# USB_USB2SS_USB2SS_CFG_0F900000h register map
Vendor: Texas Instruments
Peripheral module from a debugger description file (folder AM275x).
Registers are 32-bit, access per field, reset 0x0 unless marked. A register's access mark holds for its fields unless they carry their own. Offsets are as the file gives them; lines under a group give offsets from that group; [hi:lo] are bit positions; {n}, {i} and the like mark numbered series; 'fields as' and 'values as' point back to an identical list; <NAME> marks a mode.

## USB2SS_USB2SS_CFG
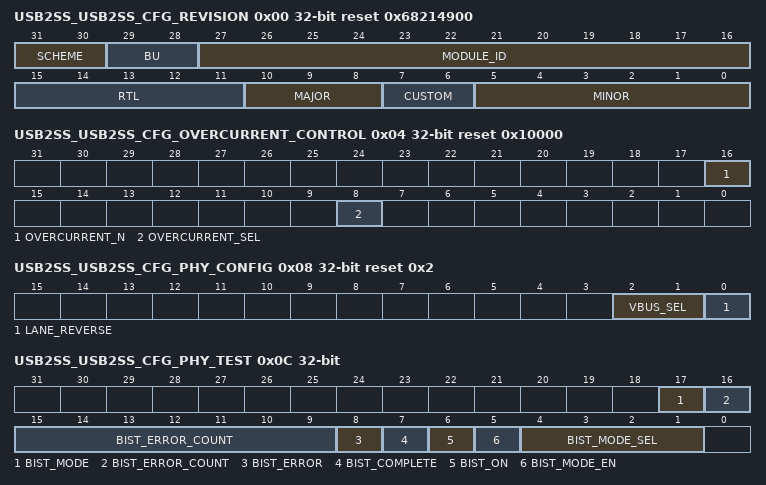
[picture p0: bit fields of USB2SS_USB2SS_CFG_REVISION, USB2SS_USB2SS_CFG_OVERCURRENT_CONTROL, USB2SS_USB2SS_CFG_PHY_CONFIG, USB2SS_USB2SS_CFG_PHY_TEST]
0x00 USB2SS_USB2SS_CFG_REVISION ro reset 0x68214900 — The Revision Register contains the major and minor revisions for the module.
  [31:30] SCHEME — PID register scheme Reset Source: cfg_srst_n
  [29:28] BU — Business Unit: 10 = Processors Reset Source: cfg_srst_n
  [27:16] MODULE_ID — Module ID Reset Source: cfg_srst_n
  [15:11] RTL — RTL revision. Will vary depending on release. Reset Source: cfg_srst_n
  [10:8] MAJOR — Major revision Reset Source: cfg_srst_n
  [7:6] CUSTOM — Custom Reset Source: cfg_srst_n
  [5:0] MINOR — Minor revision Reset Source: cfg_srst_n
0x04 USB2SS_USB2SS_CFG_OVERCURRENT_CONTROL reset 0x10000 — This register contains bits for indicating overcurrent condition on VBUS to Controller
  [16] OVERCURRENT_N rw — Overcurrent indicator to the Controller Reset Source: cfg_srst_n
  [8] OVERCURRENT_SEL rw — Overcurrent MMR select. Has to be written before setting pwrup_rst_n bit. 1 - overcurrent MMR bit is used, 0 - port_overcurrent_n input is used Reset Source: cfg_srst_n
0x08 USB2SS_USB2SS_CFG_PHY_CONFIG reset 0x2 — Wrapper register containing static settings. All bits in this register directly drive the USB2 PHY inputs. Please refer to USB2 PHY user guide for more information.
  [2:1] VBUS_SEL rw — This register directly drives the vbus_sel[1:0] input to the PHY. VBUS select - 00: VBUS = 5.25V/3.3V, 01: VBUS/3 external divider is active, so VBUS could be upto 11V. Reset Source: cfg_srst_n
  [0] LANE_REVERSE rw — This register directly drives the lane_reverse input to USB2 PHY. Lane reverse selection. When set, this bit indicates that D+ and D- lines have to be swapped. Reset Source: cfg_srst_n
0x0C USB2SS_USB2SS_CFG_PHY_TEST — Register containing PLL bypass select, BIST control and status
  [17] BIST_MODE rw — Set for bist mode. This is used for overriding PHY ports for BIST. Reset Source: cfg_srst_n
  [16:9] BIST_ERROR_COUNT ro — Number of bytes that have errors while running BIST. The count resets when bist_on is set. Reset Source: cfg_srst_n
  [8] BIST_ERROR ro — If set, this bit indicates that BIST completed with error. Reset Source: cfg_srst_n
  [7] BIST_COMPLETE ro — If set, this bit indicates that the BIST operation is completed. Reset Source: cfg_srst_n
  [6] BIST_ON rw — Setting this bit starts the BIST operation. Reset Source: cfg_srst_n
  [5] BIST_MODE_EN rw — BIST Mode Enable. 0 = BIST not enabled, 1 = BIST enabled Reset Source: cfg_srst_n
  [4:1] BIST_MODE_SEL rw — BIST Mode Selection. bist_mode_sel[3]: 0 = 8-bit interface, 1 = 16-bit interface; bist_mode_sel[2]: 0 = error injection disabled, 1 = error injection enabled; bist_mode_sel[1]: 0 = device mode, 1 = host mode; bist_mode_sel[0]: 0 = High Speed mode, 1 = Full Speed mode. Reset Source: cfg_srst_n
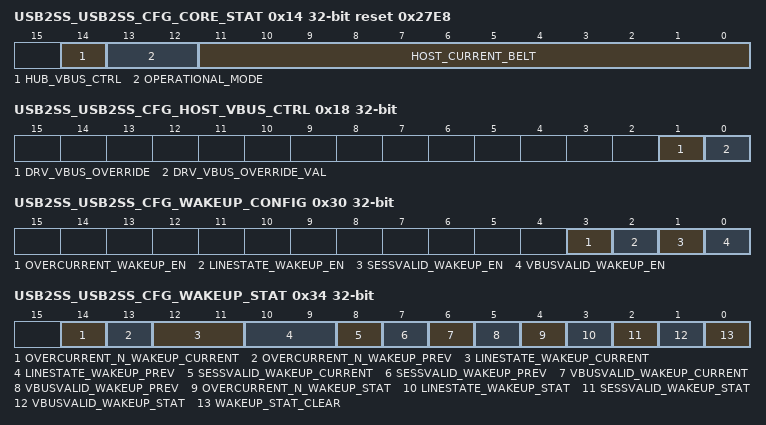
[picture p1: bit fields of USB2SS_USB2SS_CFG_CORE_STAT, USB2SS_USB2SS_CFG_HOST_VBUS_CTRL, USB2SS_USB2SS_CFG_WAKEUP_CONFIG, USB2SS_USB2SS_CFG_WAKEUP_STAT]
0x14 USB2SS_USB2SS_CFG_CORE_STAT ro reset 0x27E8 — Register containing miscellaneous status bits from the core
  [14] HUB_VBUS_CTRL — Indicates whether core is asking for VBUS to be turned on in host mode. Reset Source: cfg_srst_n
  [13:12] OPERATIONAL_MODE — Indicates current operational mode of Controller. This directly reflects the value programmed into GCTL.PRTCAPDIR Controller register. 2'b01 - Host, 2'b10 - Device. Reset Source: cfg_srst_n
  [11:0] HOST_CURRENT_BELT — Indicates minimum of all received device BELT values and the BELT value set by the Set Latency Tolerance Value command. Reset Source: cfg_srst_n
0x18 USB2SS_USB2SS_CFG_HOST_VBUS_CTRL rw — Register containing software bit for overriding drive VBUS
  [1] DRV_VBUS_OVERRIDE — Setting this bit enables drive VBUS override. Drive VBUS output reflects drv_vbus_override_val field value. Reset Source: cfg_srst_n
  [0] DRV_VBUS_OVERRIDE_VAL — Drive VBUS output override value. Reset Source: cfg_srst_n
0x1C USB2SS_USB2SS_CFG_MODE_CONTROL rw — Register containing software bit for indicating DRD mode is determined
  [0] MODE_VALID — For DRD applications, software sets this bit when the role is determined based on connect event and ID value from GPIO. Software clears this bit when a disconnect event happens and role is no longer valid. Software can also set this once during initialization for fixed role applications. Reset Source: cfg_srst_n
0x30 USB2SS_USB2SS_CFG_WAKEUP_CONFIG — Register containing low power mode wakeup enables
  [3] OVERCURRENT_WAKEUP_EN rw — overcurrent event wakeup enable Reset Source: cfg_srst_n
  [2] LINESTATE_WAKEUP_EN rw — linestate event wakeup enable Reset Source: cfg_srst_n
  [1] SESSVALID_WAKEUP_EN rw — SESSVALID event wakeup enable Reset Source: cfg_srst_n
  [0] VBUSVALID_WAKEUP_EN rw — VBUSVALID event wakeup enable Reset Source: cfg_srst_n
0x34 USB2SS_USB2SS_CFG_WAKEUP_STAT access not given — Register containing low power mode status bits. The status bits are set when the corresponding wakeup event happens and the corresponding enable in WAKEUP_CONFIG MMR is set. In addition, these bits are only set if clockstop request from PSC is active in order to ensure that these are captured only during low power mode and not during regular operation. These bits can only be set by hardware and once set, they can only be cleared by software by setting wakeup_stat_clear field.
  [14] OVERCURRENT_N_WAKEUP_CURRENT ro — overcurrent_n current value during wakeup event Reset Source: cfg_srst_n
  [13] OVERCURRENT_N_WAKEUP_PREV ro — overcurrent_n previous value during wakeup event Reset Source: cfg_srst_n
  [12:11] LINESTATE_WAKEUP_CURRENT ro — Linestate current value during wakeup event Reset Source: cfg_srst_n
  [10:9] LINESTATE_WAKEUP_PREV ro — Linestate previous value during wakeup event Reset Source: cfg_srst_n
  [8] SESSVALID_WAKEUP_CURRENT ro — SESSVALID current value during wakeup event Reset Source: cfg_srst_n
  [7] SESSVALID_WAKEUP_PREV ro — SESSVALID previous value during wakeup event Reset Source: cfg_srst_n
  [6] VBUSVALID_WAKEUP_CURRENT ro — VBUSVALID current value during wakeup event Reset Source: cfg_srst_n
  [5] VBUSVALID_WAKEUP_PREV ro — VBUSVALID previous value during wakeup event Reset Source: cfg_srst_n
  [4] OVERCURRENT_N_WAKEUP_STAT ro — overcurrent_n event wakeup status. This is only looking for change on port_overcurrent_n input and does not include overcurrent MMR. This is because wakeup is required only for a port event and for any software write to happen, SOC should already have been awake. Also SOC may be tying off port_overcurrent_n, so this event may never trigger. Reset Source: cfg_srst_n
  [3] LINESTATE_WAKEUP_STAT ro — linestate event wakeup status Reset Source: cfg_srst_n
  [2] SESSVALID_WAKEUP_STAT ro — SESSVALID event wakeup status Reset Source: cfg_srst_n
  [1] VBUSVALID_WAKEUP_STAT ro — VBUSVALID event wakeup status Reset Source: cfg_srst_n
  [0] WAKEUP_STAT_CLEAR — Clears all the *_wakeup_stat bits in this register Reset Source: cfg_srst_n (access R/W1TC)
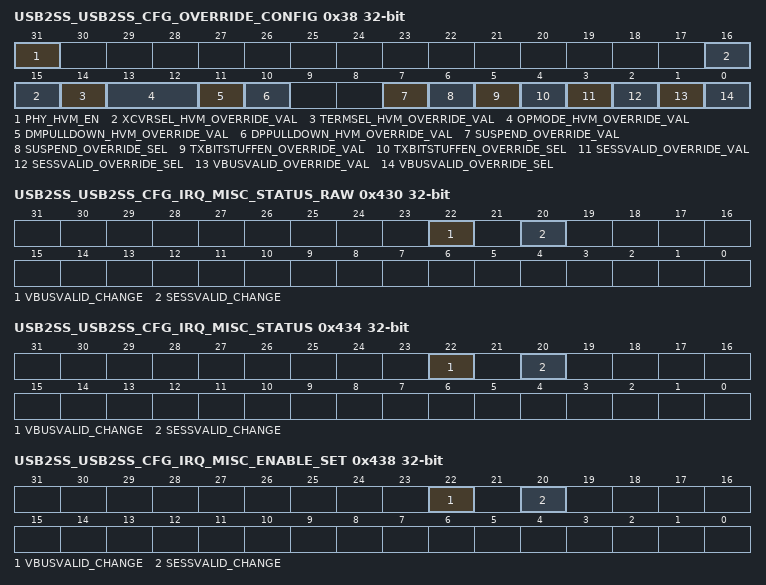
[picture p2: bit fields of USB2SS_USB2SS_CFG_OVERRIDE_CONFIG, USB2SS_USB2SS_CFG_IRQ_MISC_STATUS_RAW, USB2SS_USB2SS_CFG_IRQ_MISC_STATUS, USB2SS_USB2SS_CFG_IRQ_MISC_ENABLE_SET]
0x38 USB2SS_USB2SS_CFG_OVERRIDE_CONFIG rw — Register containing various overrides
  [31] PHY_HVM_EN — Enable PHY HVM overrides. Reset Source: cfg_srst_n
  [16:15] XCVRSEL_HVM_OVERRIDE_VAL — Override value for PHY xcvr input. The value in this field is applied to PHY xcvrsel input if phy_hvm_en bit in this register is set. Reset Source: cfg_srst_n
  [14] TERMSEL_HVM_OVERRIDE_VAL — Override value for PHY termsel input. The value in this field is applied to PHY termsel input if phy_hvm_en bit in this register is set. Reset Source: cfg_srst_n
  [13:12] OPMODE_HVM_OVERRIDE_VAL — Override value for PHY opmode input. The value in this field is applied to PHY opmode input if phy_hvm_en bit in this register is set. Reset Source: cfg_srst_n
  [11] DMPULLDOWN_HVM_OVERRIDE_VAL — Override value for PHY dmpulldown input. The value in this field is applied to PHY dmpulldown input if phy_hvm_en bit in this register is set. Reset Source: cfg_srst_n
  [10] DPPULLDOWN_HVM_OVERRIDE_VAL — Override value for PHY dppulldown input. The value in this field is applied to PHY dppulldown input if phy_hvm_en bit in this register is set. Reset Source: cfg_srst_n
  [7] SUSPEND_OVERRIDE_VAL — Suspend override value. 0 - suspendm is asserted and clockstop idle term indicates idle, 1 - suspendm is deasserted and clockstop idle term indicates non-idle. Reset Source: cfg_srst_n
  [6] SUSPEND_OVERRIDE_SEL — Suspend override selector. This has to be set to override utmi_suspend_n from Controller that goes to clockstop idle. This does not affect suspend going to PHY. Only purpose of this is to ease clockstop interface DV. Reset Source: cfg_srst_n
  [5] TXBITSTUFFEN_OVERRIDE_VAL — TXBITSTUFFENABLE override value Reset Source: cfg_srst_n
  [4] TXBITSTUFFEN_OVERRIDE_SEL — TXBITSTUFFENABLE override selector. This has to be set to override TXBITSTUFFENABLE to PHY. Reset Source: cfg_srst_n
  [3] SESSVALID_OVERRIDE_VAL — SESSVALID override value. 1 - Session is valid, 0 - Session is not valid Reset Source: cfg_srst_n
  [2] SESSVALID_OVERRIDE_SEL — SESSVALID override selector. This has to be set to override sessvalid from PHY to Controller. Reset Source: cfg_srst_n
  [1] VBUSVALID_OVERRIDE_VAL — VBUSVALID override value. 1 - VBUS is valid, 0 - VBUS is not valid Reset Source: cfg_srst_n
  [0] VBUSVALID_OVERRIDE_SEL — VBUSVALID override selector. This has to be set to override vbusvalid from PHY to Controller. Reset Source: cfg_srst_n
0x430 USB2SS_USB2SS_CFG_IRQ_MISC_STATUS_RAW access not given — The IRQ_STATUS_RAW_MISC register allows the usbss interrupt sources to be manually set when writing a 1 to a specific bit. Write 0: No action Write 1: Set event Read 0: No event pending Read 1: Event pending
  [22] VBUSVALID_CHANGE — Set when VBUSVALID changes state Reset Source: cfg_srst_n (access R/W1TS)
  [20] SESSVALID_CHANGE — Set when SESSVALID changes state Reset Source: cfg_srst_n (access R/W1TS)
0x434 USB2SS_USB2SS_CFG_IRQ_MISC_STATUS access not given — The IRQ_STATUS_MISC register allows the usbss interrupt sources to be manually cleared when writing a 1 to a specific bit. Write 0: No action Write 1: Clear event Read 0: No event pending Read 1: Event pending
  [22] VBUSVALID_CHANGE — Set when VBUSVALID changes state Reset Source: cfg_srst_n (access R/W1TC)
  [20] SESSVALID_CHANGE — Set when SESSVALID changes state Reset Source: cfg_srst_n (access R/W1TC)
0x438 USB2SS_USB2SS_CFG_IRQ_MISC_ENABLE_SET access not given — The IRQ_ENABLE_SET_MISC register allows the usbss interrupt sources to be manually enabled when writing a 1 to a specific bit. Write 0: No action Write 1: Enable event Read 0: Event is disabled Read 1: Event is enabled
  [22] VBUSVALID_CHANGE — Event enable Reset Source: cfg_srst_n (access R/W1TS)
  [20] SESSVALID_CHANGE — Event enable Reset Source: cfg_srst_n (access R/W1TS)
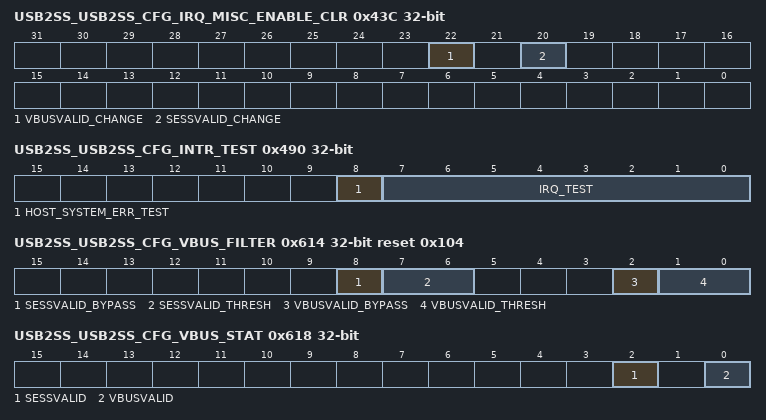
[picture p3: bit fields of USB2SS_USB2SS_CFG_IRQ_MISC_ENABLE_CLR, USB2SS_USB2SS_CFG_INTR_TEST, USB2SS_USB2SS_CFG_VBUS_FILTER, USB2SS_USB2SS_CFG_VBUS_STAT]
0x43C USB2SS_USB2SS_CFG_IRQ_MISC_ENABLE_CLR access not given — The IRQ_ENABLE_CLR_MISC register allows the usbss interrupt sources to be manually disabled when writing a 1 to a specific bit. Write 0: No action Write 1: Disable event Read 0: Event is disabled Read 1: Event is enabled
  [22] VBUSVALID_CHANGE — Event enable Reset Source: cfg_srst_n (access R/W1TC)
  [20] SESSVALID_CHANGE — Event enable Reset Source: cfg_srst_n (access R/W1TC)
0x440 USB2SS_USB2SS_CFG_IRQ_MISC_EOI rw — EOI vector for re-triggering interrupts
  [0] EOI_VECTOR — EOI vector for misc interrupt. Has to be written to 0 after ISR services misc interrupt. Reset Source: cfg_srst_n
0x490 USB2SS_USB2SS_CFG_INTR_TEST rw — Register for overriding various Controller interrupts for easy activation during DV. NOTE: This is only for internal purposes and should NOT be used during functional operation.
  [8] HOST_SYSTEM_ERR_TEST — Test for host system error interrupt. Set 1 to cause host_system_error_intr to trigger and clear this bit to clear the interrupt condition. Reset Source: cfg_srst_n
  [7:0] IRQ_TEST — Test for irq interrupts from core. Each bit sets corresponding irq_intr bit. Set 1 to each bit based on whether that interrupt needs to trigger and clear the bit in ISR to clear interrupt condition. Reset Source: cfg_srst_n
0x614 USB2SS_USB2SS_CFG_VBUS_FILTER reset 0x104 — The vbus comparator signals may be filtered by controlling these register values.
  [8] SESSVALID_BYPASS rw — 0= use filter, 1= bypass filter Reset Source: cfg_srst_n
  [7:6] SESSVALID_THRESH rw — 00= 1us,01= 100us,10= 5ms,11= 50ms. 4 utmi_clk latency for sessvalid Reset Source: cfg_srst_n
  [2] VBUSVALID_BYPASS rw — 0= use filter, 1= bypass filter for vbusvalid Reset Source: cfg_srst_n
  [1:0] VBUSVALID_THRESH rw — 00= 1us,01= 100us,10= 5ms,11= 50ms. 4 utmi_clk latency for vbusvalid Reset Source: cfg_srst_n
0x618 USB2SS_USB2SS_CFG_VBUS_STAT ro — Status bits of VBUS detected signals after filter.
  [2] SESSVALID — Filtered SESSVALID Reset Source: cfg_srst_n
  [0] VBUSVALID — Filtered VBUSVALID Reset Source: cfg_srst_n
0x708 USB2SS_USB2SS_CFG_DEBUG_CFG rw — Configuration of debug data for observation. 0x0 or 0x7 = debug outputs are tied low, 0x1 = debug outputs are UTMI interface signals, 0x2 = debug outputs are Controller debug[31:0] output 0x3 = debug outputs are Controller debug[63:32] output, 0x4 = debug outputs are clk_gate_ctrl and debug[66:64] Controller outputs, 0x5 = debug outputs are controller logic_analyzer_trace[31:0], 0x6 = debug outputs are controller logic_analyzer_trace[63:32]
  [2:0] SEL — selection of observed local signals Reset Source: cfg_srst_n
0x70C USB2SS_USB2SS_CFG_DEBUG_DATA ro — Debug data
  [31:0] VAL — tmp Reset Source: cfg_srst_n
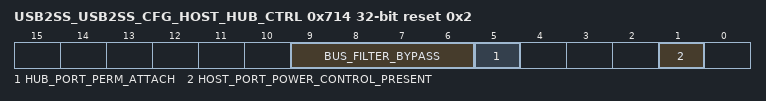
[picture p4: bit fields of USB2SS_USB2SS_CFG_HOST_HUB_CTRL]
0x714 USB2SS_USB2SS_CFG_HOST_HUB_CTRL reset 0x2 — The HOST_HUB_CTRL Register is a collection of various input signals that control the xHC controllers Host or Hub interfaces. These signals are used regardless if a Host or Hub is implemented or not.
  [9:6] BUS_FILTER_BYPASS rw — Bus Filter Bypass bit [0]: bypass the filter for vbusvalid bit bit [2]: bypass the filter for sessvalid Reset Source: cfg_srst_n
  [5] HUB_PORT_PERM_ATTACH rw — Indicates if the device attached to a downstream port is permanently attached or not. Bit 6 is the USB2 port and bit 7 is the SS port. 0 - Not permanently attached 1 - Permanently attached Reset Source: cfg_srst_n
  [1] HOST_PORT_POWER_CONTROL_PRESENT rw — This port defines the bit [3] of Capability Parameters (HCCPARAMS). Change the PPC value through the pin Port Power Control (PPC). This indicates whether the host controller implementation includes port power control. 0 - Indicates that the port does not have port power switches. 1 - Indicates that the port has port power switches. Reset Source: cfg_srst_n
